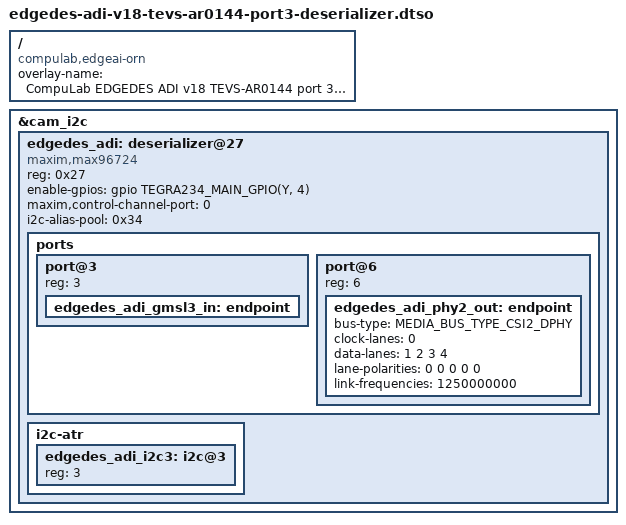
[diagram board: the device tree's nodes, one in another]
// SPDX-License-Identifier: GPL-2.0-only
// SPDX-FileCopyrightText: Copyright (c) 2026 CompuLab Ltd.

/dts-v1/;
/plugin/;

#include <dt-bindings/gpio/gpio.h>
#include <dt-bindings/gpio/tegra234-gpio.h>
#include <dt-bindings/media/video-interfaces.h>

/* Preserve the qualified TEVS-AR0144 sensor metadata from the R39 profile. */
#define TEVS_AR0144_MODE(_width, _height) \
	mclk_khz = "24000"; \
	num_lanes = "4"; \
	tegra_sinterface = "serial_c"; \
	vc_id = "0"; \
	phy_mode = "DPHY"; \
	discontinuous_clk = "yes"; \
	dpcm_enable = "false"; \
	cil_settletime = "0"; \
	lane_polarity = "0"; \
	active_w = _width; \
	active_h = _height; \
	mode_type = "yuv"; \
	pixel_phase = "uyvy"; \
	csi_pixel_bit_depth = "16"; \
	readout_orientation = "90"; \
	line_length = _width; \
	inherent_gain = "1"; \
	mclk_multiplier = "9.33"; \
	pix_clk_hz = "140000000"; \
	serdes_pix_clk_hz = "625000000"; \
	gain_factor = "16"; \
	framerate_factor = "1000000"; \
	exposure_factor = "1000000"; \
	min_gain_val = "16"; \
	max_gain_val = "170"; \
	step_gain_val = "1"; \
	default_gain = "16"; \
	min_hdr_ratio = "1"; \
	max_hdr_ratio = "1"; \
	min_framerate = "5000000"; \
	max_framerate = "60000000"; \
	step_framerate = "1"; \
	default_framerate = "60000000"; \
	min_exp_time = "13"; \
	max_exp_time = "683709"; \
	step_exp_time = "1"; \
	default_exp_time = "2495"; \
	embedded_metadata_height = "0";

/ {
	overlay-name = "CompuLab EDGEDES ADI v18 TEVS-AR0144 port 3 deserializer";
	compatible = "compulab,edgeai-orn", "nvidia,tegra234";

	fragment@0 {
		target = <&cam_i2c>;
		__overlay__ {
			status = "okay";
			#address-cells = <1>;
			#size-cells = <0>;

			edgedes_adi: deserializer@27 {
				compatible = "maxim,max96724";
				reg = <0x27>;
				/* Edge-AI EDGEDES PWDN/reset: physical low asserts reset. */
				enable-gpios = <&gpio TEGRA234_MAIN_GPIO(Y, 4) GPIO_ACTIVE_HIGH>;
				maxim,control-channel-port = <0>;
				/* Only port 3 is declared, so only link 3 is enabled. */
				i2c-alias-pool = <0x34>;

				ports {
					#address-cells = <1>;
					#size-cells = <0>;
					port@3 {
						reg = <3>;
						edgedes_adi_gmsl3_in: endpoint {
						};
					};
					/* ADI source pad 6 = GMSL inputs (4) + hardware PHY 2. */
					port@6 {
						reg = <6>;
						edgedes_adi_phy2_out: endpoint {
							bus-type = <MEDIA_BUS_TYPE_CSI2_DPHY>;
							clock-lanes = <0>;
							data-lanes = <1 2 3 4>;
							lane-polarities = <0 0 0 0 0>;
							link-frequencies = /bits/ 64 <1250000000>;
						};
					};
				};

				i2c-atr {
					#address-cells = <1>;
					#size-cells = <0>;
					edgedes_adi_i2c3: i2c@3 {
						reg = <3>;
						#address-cells = <1>;
						#size-cells = <0>;

					};
				};
			};
		};
	};
};
